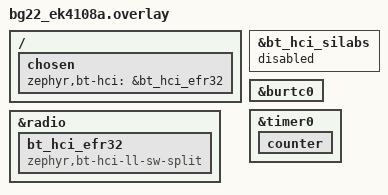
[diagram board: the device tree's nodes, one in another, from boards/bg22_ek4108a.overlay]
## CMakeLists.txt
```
cmake_minimum_required(VERSION 3.20.0)
# Scanner smoke for the EFR32 lower link layer. Kept separate from the TX
# workload so the bounded run has exactly one scheduler-owned radio role.
list(APPEND ZEPHYR_EXTRA_MODULES
    ${CMAKE_CURRENT_LIST_DIR}/../../modules/efr32-radio
    ${CMAKE_CURRENT_LIST_DIR}/../../vendor/zephyr-lang-rust)
find_package(Zephyr REQUIRED HINTS $ENV{ZEPHYR_BASE})
project(efr32_radio_rx_port)
rust_cargo_application()
if(CONFIG_RADIO_RX_PORT_CENTRAL)
  target_sources(app PRIVATE src/central.c)
endif()
```

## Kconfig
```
# Test-only configuration for the EFR32 QEMU scanner workload.

menu "EFR32 radio RX-port test"

config RADIO_RX_PORT_ACTIVE_SCAN
	bool "Exercise active scanning in the QEMU RX-port workload"
	depends on BT_OBSERVER
	default n
	help
	  Use the host's active scan parameter rather than the default passive
	  parameter. This is solely an in-tree QEMU integration workload: it
	  expects the EFR32 HAL's separately gated QEMU RX-to-TX turn-around to
	  send a staged SCAN_REQ, then receive the advertiser's SCAN_RSP. Do not
	  select it for a hardware build; silicon packet-end/TIFS semantics are
	  not established.

config RADIO_RX_PORT_CENTRAL
	bool "Exercise central connection establishment in the QEMU RX-port workload"
	depends on BT_CENTRAL
	default n
	help
	  Replace the scanner-only workload with a central that scans for the
	  connectable advertiser and issues bt_conn_le_create(). This is solely
	  an in-tree QEMU integration workload: it requires the QEMU RX-to-TX
	  turn-around to deliver CONNECT_IND to the advertiser and the first
	  connection-event packet back. Do not select it for a hardware build.

config RADIO_RX_PORT_PEER_ADDR
	string "Address of the advertiser the Central connects to"
	depends on RADIO_RX_PORT_CENTRAL
	default ""
	help
	  "XX:XX:XX:XX:XX:XX": connect only to a connectable advertisement from this
	  address (on silicon, where other advertisers are in range). Empty: the first
	  connectable advertisement heard.

config RADIO_RX_PORT_RECONNECT_MS
	int "Hold each link this long, then disconnect and connect again (0: hold)"
	depends on RADIO_RX_PORT_CENTRAL
	default 0
	help
	  Nonzero: instead of the GATT rounds, the Central repeats connection set-up
	  (scan, CONNECT_IND, first anchor) for measurements on silicon.

config RADIO_RX_PORT_PAIRING
	bool "Pair with LE Secure Connections and a passkey before the GATT rounds"
	depends on RADIO_RX_PORT_CENTRAL && BT_SMP
	help
	  Once connected, request security level 4 (LE Secure Connections, authenticated),
	  enter RADIO_RX_PORT_PASSKEY as a keyboard-only device, and run the GATT rounds only on
	  the encrypted link. prj-central-pairing.conf.

config RADIO_RX_PORT_PASSKEY
	int "Passkey the Central enters"
	depends on RADIO_RX_PORT_PAIRING
	range 0 999999
	default 123456
	help
	  The radio-port advertiser's RADIO_PORT_PASSKEY, or the product's (the Jenkins
	  one-at-a-time hash of its serial modulo 10^6, crates/owo-core proto::pairing_code();
	  426134 for the default serial 000000000000).

config RADIO_RX_PORT_PEER_PRODUCT
	bool "The Peripheral is the product image"
	depends on RADIO_RX_PORT_PAIRING
	help
	  Run the GATT rounds on the product's "Test" characteristic (src/ble.rs: a 20-octet value
	  written and read back, authenticated encrypted link only) instead of the radio-port
	  test characteristic. prj-central-product.conf.

config RADIO_RX_PORT_PEER_PRODUCT_STIM
	bool "Command stimulation on the product over the link"
	depends on RADIO_RX_PORT_PEER_PRODUCT
	help
	  Between the GATT rounds, command the product as its app does, over the encrypted link:
	  enable notifications on "Start / Stop" and "Extra 2", then every
	  CENTRAL_STIM_EVERY rounds write the pulse widths, Start (0x25), a 5 s frame and a frame
	  with a bad checksum (answered by a notification), and every second cycle Stop (0x00).
	  For measuring the product's Bluetooth RX thread on the stimulation paths
	  (write_cb, the output's stop and start, notifications). prj-central-product-stim.conf.

endmenu

# Module defaults that must precede Zephyr's own (modules/efr32-radio/Kconfig.defaults).
osource "$(ZEPHYR_EFR32_RADIO_MODULE_DIR)/Kconfig.defaults"
source "Kconfig.zephyr"
```

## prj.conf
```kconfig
# Scanner-only QEMU smoke using Zephyr's split controller and our EFR32 LLL.
CONFIG_RUST=y
CONFIG_BT=y
CONFIG_BT_OBSERVER=y
CONFIG_BT_DEVICE_NAME="efr32-radio-rx-port"
# The smoke must execute the actual EFR32 HAL MMIO path, rather than the
# compile-only stub configuration.
CONFIG_EFR32_RADIO_STUB_REGISTERS=n
# This scanner image is run only under the in-tree EFR32 QEMU model. The
# option consumes QEMU's synthetic BUFC channel-2 class-6/7 records; leave it
# disabled in every hardware configuration because the silicon producer and
# RXDONE ordering remain unproven.
CONFIG_EFR32_RADIO_QEMU_RX_DESCRIPTOR=y
CONFIG_ENTROPY_GENERATOR=y
# System time and every kernel or radio wake-up come from the scheduler clock: BURTC
# across deep sleep, TIMER0 (HFXO) while the CPU runs.
CONFIG_CLOCK_EVENT_SYSTEM_TIMER=y
CONFIG_SILABS_BURTC_CLOCK_EVENT=y
CONFIG_COUNTER_SILABS_BURTC=n
CONFIG_COUNTER=y
CONFIG_COUNTER_SILABS_TIMER_CLOCK_EVENT=y
CONFIG_COUNTER_GECKO_STIMER=n
CONFIG_LOG=y
# A clock event delivered after its deadline (plus tolerance) is a fault in test builds.
# The lower link layer runs in meta-IRQ threads, not interrupts (modules/efr32-radio/hal/ll_threads.c):
# the LLL and radio jobs at the first priority, the ULL worker at the second.
CONFIG_NUM_METAIRQ_PRIORITIES=2
# This image runs in QEMU: its deadlines and budgets use the model's measured times
# (modules/efr32-radio/Kconfig, EFR32_RADIO_TIMING). The hardware profile selects silicon's.
CONFIG_EFR32_RADIO_TIMING_QEMU=y
# BT_CTLR_ZLI is only settable with the controller's advanced options visible.
CONFIG_BT_CTLR_ADVANCED_FEATURES=y
CONFIG_BT_CTLR_ZLI=n
# Interrupts only publish work now. One analyzer run peaked at 368 bytes, but
# nested interrupts with FP context overflowed 768.
CONFIG_ISR_STACK_SIZE=1024
```

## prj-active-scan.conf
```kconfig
# Opt-in test profile, merged with prj.conf using EXTRA_CONF_FILE: an active scanner on the
# silicon path. No QEMU-only seam: the sequencer sends the SCAN_REQ at T_IFS after the received
# advertisement and turns to receive the SCAN_RSP (the staged scanner, docs/radio-tables.md
# 7.87).
CONFIG_RADIO_RX_PORT_ACTIVE_SCAN=y
CONFIG_EFR32_RADIO_QEMU_TIFS=n
CONFIG_EFR32_RADIO_QEMU_RX_DESCRIPTOR=n
```

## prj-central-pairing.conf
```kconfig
# Pairing profile, merged after prj-central.conf: the Central pairs (LE Secure Connections,
# passkey entry, security level 4) before its GATT rounds (src/central.c). Peripheral:
# tests/radio-port with prj-pairing.conf, or the product (RADIO_RX_PORT_PASSKEY its passkey).
CONFIG_BT_SMP=y
CONFIG_BT_SMP_SC_PAIR_ONLY=y
CONFIG_RADIO_RX_PORT_PAIRING=y
```

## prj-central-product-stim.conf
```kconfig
# The product image as the Peripheral, merged after prj-central-product.conf: stimulation
# commands over the encrypted link between the GATT rounds (Kconfig RADIO_RX_PORT_PEER_PRODUCT_STIM).
CONFIG_RADIO_RX_PORT_PEER_PRODUCT_STIM=y
```

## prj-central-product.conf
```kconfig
# The product image as the Peripheral, merged after prj-central.conf and
# prj-central-pairing.conf: its passkey for the default serial (000000000000) and its "Test"
# characteristic for the GATT rounds (Kconfig RADIO_RX_PORT_PEER_PRODUCT).
CONFIG_RADIO_RX_PORT_PASSKEY=426134
CONFIG_RADIO_RX_PORT_PEER_PRODUCT=y
```

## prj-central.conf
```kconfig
# Opt-in test profile, merged with prj.conf using EXTRA_CONF_FILE. It replaces the scanner-only
# workload with a central that connects to the radio-port advertiser (src/central.c). It runs the
# hardware configuration, the silicon path: the initiator's CONNECT_IND is the sequencer's RX->TX
# response at T_IFS and its anchors are TX launches held to the sleep clock's 16 us
# (docs/radio-tables.md 7.79). The QEMU-configuration seams' T_IFS starts at the LLL callback, so
# their CONNECT_IND reaches the advertiser after its window. Do not select it for a hardware
# build.
CONFIG_BT_OBSERVER=n
CONFIG_BT_CENTRAL=y
CONFIG_RADIO_RX_PORT_CENTRAL=y
# The Central writes and reads back the advertiser's test characteristic over the link.
CONFIG_BT_GATT_CLIENT=y
CONFIG_EFR32_RADIO_QEMU_TIFS=n
CONFIG_EFR32_RADIO_QEMU_RX_DESCRIPTOR=n
# The workload is C: main needs less than the Rust default.
CONFIG_MAIN_STACK_SIZE=1536
# Same connection-path budget as the advertiser's prj-connection.conf. QEMU-test headroom only;
# the hardware profile keeps the measured values. The log buffer shrinks to fund the stacks.
CONFIG_EFR32_RADIO_ULL_STACK_SIZE=896
CONFIG_EFR32_RADIO_LAUNCH_STACK_SIZE=640
CONFIG_EFR32_RADIO_COMPLETION_STACK_SIZE=960
CONFIG_LOG_BUFFER_SIZE=256
# As in prj-connection.conf: the QEMU M33 runs lll_conn's turnaround callbacks past their
# spec-derived start-by deadlines (7.79), so this QEMU-only profile counts missed deadlines
# instead of shutting the radio down.
CONFIG_SCHED_DEADLINE_MISS_COUNT=y
```

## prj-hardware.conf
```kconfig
# Hardware scanner on the BGM220 Explorer Kit (board bgm220_ek4314a/bgm220pc22hna), merged with
# prj.conf using EXTRA_CONF_FILE. The QEMU receive and TIFS seams do not describe silicon; the
# receiver opens from OFF (SWRXEN -> RXWARM -> RXSEARCH, docs/radio-tables.md 7.80).
CONFIG_EFR32_RADIO_QEMU_TIFS=n
CONFIG_EFR32_RADIO_QEMU_RX_DESCRIPTOR=n
# Budgets, paths and the interrupt allowance behind every deadline: the silicon measurements.
CONFIG_EFR32_RADIO_TIMING_QEMU=n
CONFIG_EFR32_RADIO_TIMING_SILICON=y
# The measured LL stack budget of tests/radio-port/prj-hardware.conf.
CONFIG_EFR32_RADIO_ULL_STACK_SIZE=960
CONFIG_EFR32_RADIO_LLL_STACK_SIZE=960
CONFIG_SCHED_DEADLINE_MISS_HISTORY=4
CONFIG_EFR32_RADIO_BRINGUP_TRACE=n
```

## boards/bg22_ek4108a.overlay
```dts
/* Use Zephyr's split controller rather than Silicon Labs' binary controller. */
&bt_hci_silabs {
	status = "disabled";
};

&radio {
	bt_hci_efr32: bt_hci_efr32 {
		compatible = "zephyr,bt-hci-ll-sw-split";
		status = "okay";
	};
};

/ {
	chosen {
		zephyr,bt-hci = &bt_hci_efr32;
	};
};

&burtc0 {
	status = "okay";
};

/* HFXO-clocked 32-bit TIMER0: the scheduler clock's active-state provider. */
&timer0 {
	status = "okay";

	counter {
		status = "okay";
	};
};
```

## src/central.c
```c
/*
 * Central connection workload: scan for the connectable advertiser, then create an LE link and
 * report the host's connected and disconnected callbacks.
 * SPDX-License-Identifier: Apache-2.0
 *
 * This is the QEMU-only proof that the ported lower link layer runs the connection exchange:
 * the central's CONNECT_IND reaches the advertiser, connection events follow, and Zephyr's host
 * on the central reports an established link. It is not a claim about RF airtime or silicon
 * timing. Written in C because the Rust bindings expose only <zephyr/bluetooth/bluetooth.h>,
 * which no longer declares the connection API.
 */
#include <zephyr/kernel.h>
#include <zephyr/bluetooth/bluetooth.h>
#include <zephyr/bluetooth/conn.h>
#include <zephyr/bluetooth/gatt.h>
#include <zephyr/bluetooth/uuid.h>

/* Scan window 30 ms and interval 60 ms, Zephyr's BT_GAP_SCAN_FAST_* values. */
#define CENTRAL_SCAN_INTERVAL BT_GAP_SCAN_FAST_INTERVAL
#define CENTRAL_SCAN_WINDOW BT_GAP_SCAN_FAST_WINDOW

/*
 * Connection parameters: 7.5..50 ms interval (1.25 ms units), no peripheral latency, a 5 s
 * supervision timeout (10 ms units). The minimum interval is deliberate: a bounded QEMU run then
 * crosses many connection events after the link is up.
 */
#define CENTRAL_CONN_INTERVAL_MIN 0x0006
#define CENTRAL_CONN_INTERVAL_MAX 0x0028
#define CENTRAL_CONN_TIMEOUT 500

static bt_addr_le_t peer;
static bool create_issued;
static struct bt_conn *conn;
/* Given when the link is up: the GATT loop then starts. */
static K_SEM_DEFINE(link_up, 0, 1);

/* Given at every connected and disconnected callback (reconnecting workload). */
static K_SEM_DEFINE(link_changed, 0, 2);
static uint8_t connect_err;

static void connected(struct bt_conn *c, uint8_t err)
{
	ARG_UNUSED(c);
	/* Zero: the host accepted the controller's connection complete event. */
	printk("central_connected: %u\n", err);
	connect_err = err;
	if (err == 0U) {
		k_sem_give(&link_up);
	}
	k_sem_give(&link_changed);
}

static void disconnected(struct bt_conn *c, uint8_t reason)
{
	ARG_UNUSED(c);
	printk("central_disconnected: 0x%02x at %lld ms\n", reason, k_uptime_get());
	k_sem_give(&link_changed);
}

#if defined(CONFIG_RADIO_RX_PORT_PAIRING)
/* Given when the link reached security level 4 (LE Secure Connections, authenticated). */
static K_SEM_DEFINE(secured, 0, 1);
static int64_t security_requested_ms;

static void security_changed(struct bt_conn *c, bt_security_t level, enum bt_security_err err)
{
	ARG_UNUSED(c);
	printk("central_security: level %d err %d after %lld ms\n", level, err,
	       k_uptime_get() - security_requested_ms);
	if (err == BT_SECURITY_ERR_SUCCESS && level >= BT_SECURITY_L4) {
		k_sem_give(&secured);
	}
}

/* Keyboard-only: the Central enters the Peripheral's passkey. */
static void passkey_entry(struct bt_conn *c)
{
	printk("central_passkey_entry: %06u\n", CONFIG_RADIO_RX_PORT_PASSKEY);
	(void)bt_conn_auth_passkey_entry(c, CONFIG_RADIO_RX_PORT_PASSKEY);
}

static void auth_cancel(struct bt_conn *c)
{
	ARG_UNUSED(c);
	printk("central_pairing_cancelled\n");
}

static void pairing_complete(struct bt_conn *c, bool bonded)
{
	ARG_UNUSED(c);
	printk("central_paired: bonded %d\n", bonded);
}

static void pairing_failed(struct bt_conn *c, enum bt_security_err reason)
{
	ARG_UNUSED(c);
	printk("central_pairing_failed: %d\n", reason);
}

static const struct bt_conn_auth_cb auth_cb = {
	.passkey_entry = passkey_entry,
	.cancel = auth_cancel,
};

static struct bt_conn_auth_info_cb auth_info_cb = {
	.pairing_complete = pairing_complete,
	.pairing_failed = pairing_failed,
};
#endif /* CONFIG_RADIO_RX_PORT_PAIRING */

BT_CONN_CB_DEFINE(central_conn_callbacks) = {
	.connected = connected,
	.disconnected = disconnected,
#if defined(CONFIG_RADIO_RX_PORT_PAIRING)
	.security_changed = security_changed,
#endif
};

/*
 * The report's address is valid only during this callback, so the peer is copied before the
 * create request. Scanning stops first: the scan and initiate windows compete for the radio.
 */
static void scan_result(const bt_addr_le_t *addr, int8_t rssi, uint8_t adv_type,
			struct net_buf_simple *buf)
{
	const struct bt_conn_le_create_param create_param =
		BT_CONN_LE_CREATE_PARAM_INIT(0, CENTRAL_SCAN_INTERVAL, CENTRAL_SCAN_WINDOW);
	const struct bt_le_conn_param conn_param =
		BT_LE_CONN_PARAM_INIT(CENTRAL_CONN_INTERVAL_MIN, CENTRAL_CONN_INTERVAL_MAX, 0,
				      CENTRAL_CONN_TIMEOUT);
	int err;

	ARG_UNUSED(rssi);
	ARG_UNUSED(buf);
	if (addr == NULL || create_issued || addr->type == BT_ADDR_LE_ANONYMOUS ||
	    (adv_type != BT_GAP_ADV_TYPE_ADV_IND && adv_type != BT_GAP_ADV_TYPE_ADV_DIRECT_IND)) {
		return;
	}
	if (CONFIG_RADIO_RX_PORT_PEER_ADDR[0] != '\0') {
		bt_addr_t want;

		if (bt_addr_from_str(CONFIG_RADIO_RX_PORT_PEER_ADDR, &want) != 0 ||
		    !bt_addr_eq(&addr->a, &want)) {
			return;
		}
	}
	bt_addr_le_copy(&peer, addr);
	create_issued = true;
	printk("scan_stop: %d\n", bt_le_scan_stop());
	err = bt_conn_le_create(&peer, &create_param, &conn_param, &conn);
	printk("conn_le_create: %d\n", err);
}

/*
 * GATT over the link: find the advertiser's test characteristic (tests/radio-port/src/gatt.c),
 * then once per CENTRAL_GATT_PERIOD_MS write a counter to it and read it back. Every result is
 * counted; a summary is printed every CENTRAL_GATT_REPORT_EVERY rounds.
 */
#define CENTRAL_GATT_PERIOD_MS 1000
#define CENTRAL_GATT_REPORT_EVERY 30
#define CENTRAL_GATT_TIMEOUT_MS 5000
#if defined(CONFIG_RADIO_RX_PORT_PEER_PRODUCT)
/* The product's "Test" characteristic (src/ble.rs U_TEST): it keeps a written 20-octet frame and
 * returns it on read, both only over an authenticated encrypted link.
 */
static const struct bt_uuid_128 test_chr_uuid = BT_UUID_INIT_128(
	BT_UUID_128_ENCODE(0xb1f5a059, 0xc717, 0x11e4, 0x8731, 0x1681e6b88ec1));
#define CENTRAL_VALUE_LEN 20U
#else
static const struct bt_uuid_128 test_chr_uuid = BT_UUID_INIT_128(
	BT_UUID_128_ENCODE(0x5b2a1c01, 0x6f3e, 0x4c1d, 0x9a7b, 0x0e1f2d3c4b5a));
#define CENTRAL_VALUE_LEN 4U
#endif
static K_SEM_DEFINE(gatt_done, 0, 1);
static uint16_t value_handle;
static uint8_t gatt_err;
static uint8_t read_back[CENTRAL_VALUE_LEN];
static uint16_t read_len;

static uint8_t discovered(struct bt_conn *c, const struct bt_gatt_attr *attr,
			  struct bt_gatt_discover_params *params)
{
	ARG_UNUSED(c);
	if (attr != NULL) {
		value_handle = ((const struct bt_gatt_chrc *)attr->user_data)->value_handle;
	}
	k_sem_give(&gatt_done);
	ARG_UNUSED(params);
	return BT_GATT_ITER_STOP;
}

static void written(struct bt_conn *c, uint8_t err, struct bt_gatt_write_params *params)
{
	ARG_UNUSED(c);
	ARG_UNUSED(params);
	gatt_err = err;
	k_sem_give(&gatt_done);
}

static uint8_t read_cb(struct bt_conn *c, uint8_t err, struct bt_gatt_read_params *params,
		       const void *data, uint16_t length)
{
	ARG_UNUSED(c);
	ARG_UNUSED(params);
	if (data != NULL) {
		read_len = MIN(length, sizeof(read_back));
		memcpy(read_back, data, read_len);
		return BT_GATT_ITER_CONTINUE;
	}
	gatt_err = err;
	k_sem_give(&gatt_done);
	return BT_GATT_ITER_STOP;
}

static int gatt_wait(void)
{
	return k_sem_take(&gatt_done, K_MSEC(CENTRAL_GATT_TIMEOUT_MS));
}

#if defined(CONFIG_RADIO_RX_PORT_PEER_PRODUCT_STIM)
/*
 * The product's stimulation characteristics (src/ble.rs): two UUID bases,
 * ...-C6A9-11E4-8731-1681E6B88EC1 and ...-C717-11E4-8731-1681E6B88EC1.
 */
static const struct bt_uuid_128 widths_uuid = BT_UUID_INIT_128(
	BT_UUID_128_ENCODE(0x7764e556, 0xc6a9, 0x11e4, 0x8731, 0x1681e6b88ec1));
static const struct bt_uuid_128 run_uuid = BT_UUID_INIT_128(
	BT_UUID_128_ENCODE(0x7764eda8, 0xc6a9, 0x11e4, 0x8731, 0x1681e6b88ec1));
static const struct bt_uuid_128 frame_uuid = BT_UUID_INIT_128(
	BT_UUID_128_ENCODE(0x77646be3, 0xc717, 0x11e4, 0x8731, 0x1681e6b88ec1));
static const struct bt_uuid_128 extra2_uuid = BT_UUID_INIT_128(
	BT_UUID_128_ENCODE(0x776416cb, 0xc717, 0x11e4, 0x8731, 0x1681e6b88ec1));
/* A stimulation cycle every CENTRAL_STIM_EVERY rounds (seconds). */
#define CENTRAL_STIM_EVERY 10U
/*
 * The stimulus of sim/scripts/make_scenarios.py: table widths 0x49, then a 5 s frame (wire
 * channel 0, level 20, 50 Hz) and the same frame with its checksum octet changed.
 */
static const uint8_t stim_widths[10] = { 0x49, 0x49, 0x49, 0x49, 0x49,
					 0x49, 0x49, 0x49, 0x49, 0x49 };
static const uint8_t stim_frame[20] = { 0x14, 0x00, 0x00, 0x00, 0x00, 0x00, 0x00,
					0x00, 0x00, 0x00, 0x32, 0x00, 0x32, 0x32,
					0x00, 0x00, 0x00, 0x01, 0x00, 0x27 };
static uint16_t found_handle;

static uint8_t found(struct bt_conn *c, const struct bt_gatt_attr *attr,
		     struct bt_gatt_discover_params *params)
{
	ARG_UNUSED(c);
	if (attr != NULL) {
		found_handle = params->type == BT_GATT_DISCOVER_CHARACTERISTIC
			? ((const struct bt_gatt_chrc *)attr->user_data)->value_handle
			: attr->handle;
	}
	k_sem_give(&gatt_done);
	return BT_GATT_ITER_STOP;
}

/* The value handle of the characteristic `uuid`, or of the CCC descriptor after `after`. */
static uint16_t find_handle(const struct bt_uuid *uuid, uint16_t after)
{
	struct bt_gatt_discover_params p = {
		.uuid = uuid,
		.func = found,
		.start_handle = after != 0U ? after + 1U : BT_ATT_FIRST_ATTRIBUTE_HANDLE,
		.end_handle = after != 0U ? after + 2U : BT_ATT_LAST_ATTRIBUTE_HANDLE,
		.type = after != 0U ? BT_GATT_DISCOVER_DESCRIPTOR : BT_GATT_DISCOVER_CHARACTERISTIC,
	};

	found_handle = 0U;
	if (bt_gatt_discover(conn, &p) != 0 || gatt_wait() != 0) {
		return 0U;
	}
	return found_handle;
}

static int stim_write(uint16_t handle, const void *data, uint16_t len)
{
	struct bt_gatt_write_params w = {
		.func = written, .handle = handle, .data = data, .length = len,
	};

	gatt_err = 0U;
	if (bt_gatt_write(conn, &w) != 0 || gatt_wait() != 0) {
		return -1;
	}
	return gatt_err;
}

static uint16_t widths_handle, run_handle, frame_handle;

static void stim_setup(void)
{
	static const uint8_t notify_on[2] = { 0x01, 0x00 };
	uint16_t extra2_handle;

	widths_handle = find_handle(&widths_uuid.uuid, 0U);
	run_handle = find_handle(&run_uuid.uuid, 0U);
	frame_handle = find_handle(&frame_uuid.uuid, 0U);
	extra2_handle = find_handle(&extra2_uuid.uuid, 0U);
	printk("stim_discover: widths 0x%04x run 0x%04x frame 0x%04x extra2 0x%04x\n",
	       widths_handle, run_handle, frame_handle, extra2_handle);
	/* Notifications on: the product's notifications then go out over the link. */
	printk("stim_ccc: run %d extra2 %d\n",
	       stim_write(find_handle(BT_UUID_GATT_CCC, run_handle), notify_on, 2U),
	       stim_write(find_handle(BT_UUID_GATT_CCC, extra2_handle), notify_on, 2U));
}

static void stim_cycle(uint32_t cycle)
{
	static const uint8_t start = 0x25;
	static const uint8_t stop = 0x00;
	uint8_t bad[sizeof(stim_frame)];
	int w, s, f, b, x = 0;

	memcpy(bad, stim_frame, sizeof(bad));
	bad[sizeof(bad) - 1U] ^= 0xffU;
	w = stim_write(widths_handle, stim_widths, sizeof(stim_widths));
	s = stim_write(run_handle, &start, 1U);
	f = stim_write(frame_handle, stim_frame, sizeof(stim_frame));
	b = stim_write(frame_handle, bad, sizeof(bad));
	if (cycle % 2U == 1U) {
		x = stim_write(run_handle, &stop, 1U);
	}
	printk("stim_cycle: %u widths %d start %d frame %d bad-frame %d stop %d\n", cycle, w, s,
	       f, b, x);
}
#endif /* CONFIG_RADIO_RX_PORT_PEER_PRODUCT_STIM */

static void gatt_loop(void)
{
	struct bt_gatt_discover_params discover = {
		.uuid = &test_chr_uuid.uuid,
		.func = discovered,
		.start_handle = BT_ATT_FIRST_ATTRIBUTE_HANDLE,
		.end_handle = BT_ATT_LAST_ATTRIBUTE_HANDLE,
		.type = BT_GATT_DISCOVER_CHARACTERISTIC,
	};
	uint32_t rounds = 0U;
	uint32_t ok = 0U;
	uint32_t failed = 0U;

	if (bt_gatt_discover(conn, &discover) != 0 || gatt_wait() != 0 || value_handle == 0U) {
		printk("gatt_discover: failed\n");
		return;
	}
	printk("gatt_discover: handle 0x%04x\n", value_handle);
#if defined(CONFIG_RADIO_RX_PORT_PEER_PRODUCT_STIM)
	stim_setup();
#endif
	for (;;) {
		uint32_t counter = rounds + 1U;
		uint8_t value[CENTRAL_VALUE_LEN] = { 0 };
		struct bt_gatt_write_params write = {
			.func = written, .handle = value_handle, .data = value,
			.length = sizeof(value),
		};
		struct bt_gatt_read_params read = {
			.func = read_cb, .handle_count = 1, .single.handle = value_handle,
		};
		bool good;

		memcpy(value, &counter, sizeof(counter));
		k_msleep(CENTRAL_GATT_PERIOD_MS);
		gatt_err = 0U;
		read_len = 0U;
		good = bt_gatt_write(conn, &write) == 0 && gatt_wait() == 0 && gatt_err == 0U &&
		       bt_gatt_read(conn, &read) == 0 && gatt_wait() == 0 && gatt_err == 0U &&
		       read_len == sizeof(value) && memcmp(read_back, value, sizeof(value)) == 0;
		rounds++;
		if (good) {
			ok++;
		} else {
			failed++;
			printk("gatt_rw: round %u failed (err 0x%02x, read %u)\n", rounds, gatt_err,
			       read_len);
		}
		if (rounds % CENTRAL_GATT_REPORT_EVERY == 0U) {
			printk("gatt_rw: %u rounds, %u ok, %u failed\n", rounds, ok, failed);
		}
#if defined(CONFIG_RADIO_RX_PORT_PEER_PRODUCT_STIM)
		if (rounds % CENTRAL_STIM_EVERY == 0U) {
			stim_cycle(rounds / CENTRAL_STIM_EVERY);
		}
#endif
	}
}

void radio_rx_port_central_start(void)
{
	const struct bt_le_scan_param scan = {
		.type = BT_LE_SCAN_TYPE_ACTIVE,
		.interval = CENTRAL_SCAN_INTERVAL,
		.window = CENTRAL_SCAN_WINDOW,
	};
	int err = bt_enable(NULL);

	printk("bt_enable: %d\n", err);
	if (err != 0) {
		return;
	}
#if defined(CONFIG_RADIO_RX_PORT_PAIRING)
	printk("auth_register: %d %d\n", bt_conn_auth_cb_register(&auth_cb),
	       bt_conn_auth_info_cb_register(&auth_info_cb));
#endif
	printk("scan_start: %d\n", bt_le_scan_start(&scan, scan_result));
	/*
	 * Reconnecting workload: hold each link RADIO_RX_PORT_RECONNECT_MS, disconnect, scan and
	 * connect again, so one boot repeats connection set-up.
	 */
	for (uint32_t cycle = 1U; CONFIG_RADIO_RX_PORT_RECONNECT_MS > 0; cycle++) {
		(void)k_sem_take(&link_changed, K_FOREVER);
		if (connect_err == 0U) {
			k_sem_reset(&link_up);
			if (k_sem_take(&link_changed, K_MSEC(CONFIG_RADIO_RX_PORT_RECONNECT_MS)) != 0) {
				printk("central_cycle: %u disconnect %d\n", cycle,
				       bt_conn_disconnect(conn, BT_HCI_ERR_REMOTE_USER_TERM_CONN));
				(void)k_sem_take(&link_changed, K_FOREVER);
			}
		}
		bt_conn_unref(conn);
		conn = NULL;
		create_issued = false;
		printk("scan_start: %d\n", bt_le_scan_start(&scan, scan_result));
	}
	k_sem_take(&link_up, K_FOREVER);
#if defined(CONFIG_RADIO_RX_PORT_PAIRING)
	/* Pair (LE Secure Connections, passkey entry) and encrypt before any GATT access. */
	security_requested_ms = k_uptime_get();
	printk("set_security: %d\n", bt_conn_set_security(conn, BT_SECURITY_L4));
	if (k_sem_take(&secured, K_SECONDS(120)) != 0) {
		printk("central_security: timeout\n");
		return;
	}
#endif
	gatt_loop();
}
```
